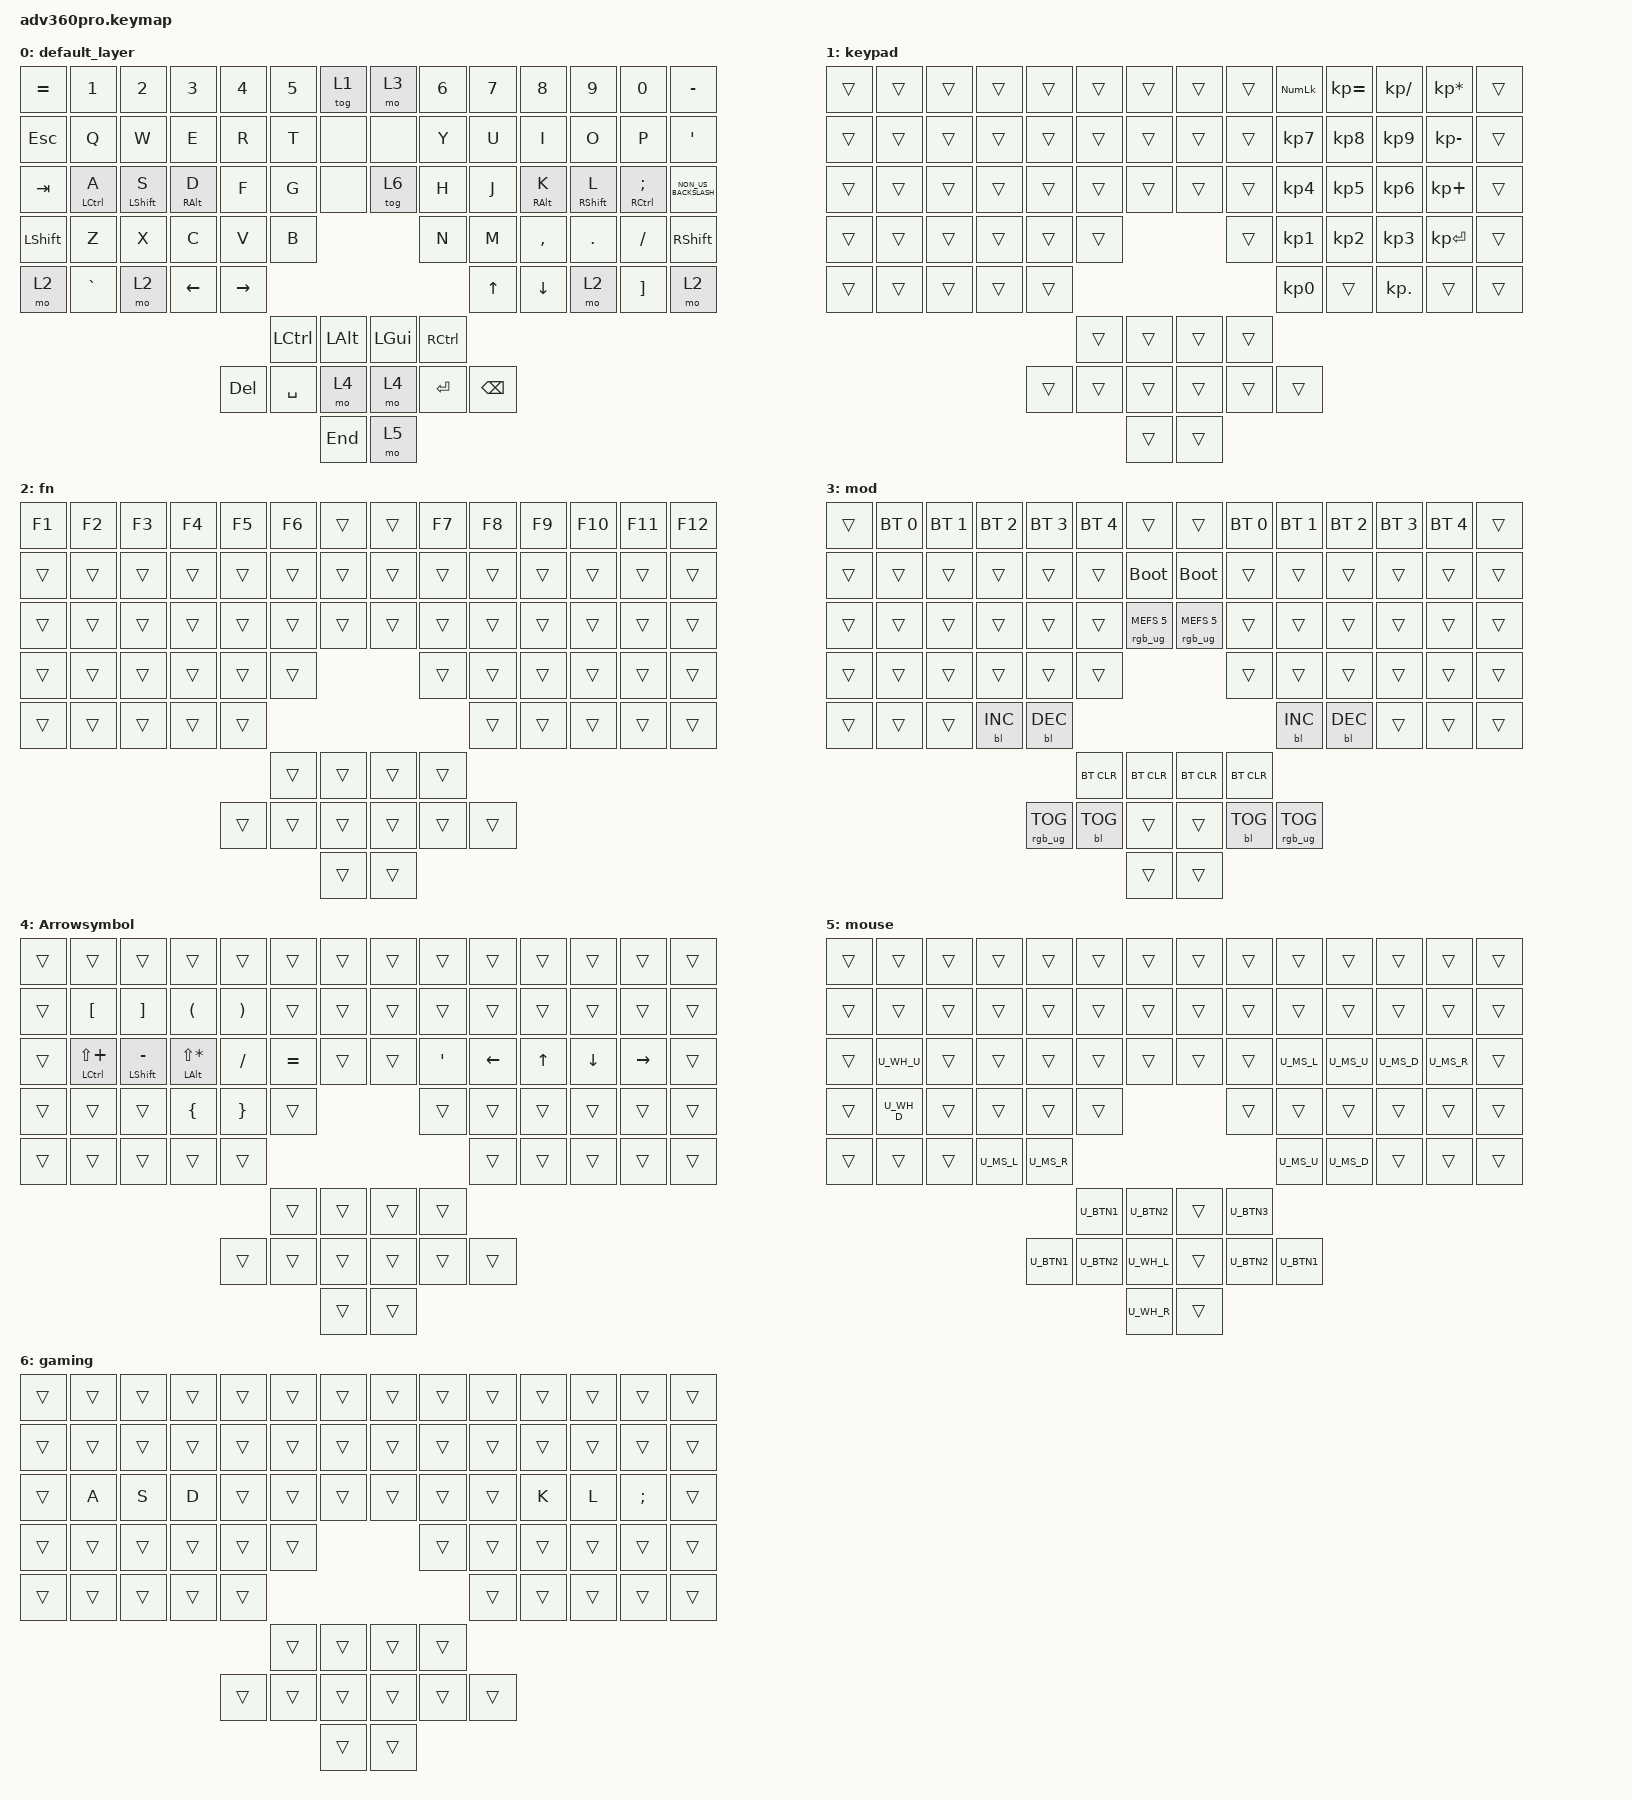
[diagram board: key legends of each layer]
#include <behaviors.dtsi>
#include <dt-bindings/zmk/backlight.h>
#include <dt-bindings/zmk/bt.h>
#include <dt-bindings/zmk/keys.h>
#include <dt-bindings/zmk/rgb.h>
#include "mouse.dtsi"
#define ___ &trans
/ {
    behaviors {
        hm_l: hm_l {
            compatible = "zmk,behavior-hold-tap";
            label = "HM_L";
            bindings =
                <&kp>,
                <&kp>;

            #binding-cells = <2>;
            flavor = "balanced";          
            tapping-term-ms = <280>;
            quick-tap-ms = <175>;                // repeat on tap-into-hold
            global-quick-tap-ms = <150>;         // requires PR #1387
            bindings = <&kp>, <&kp>;
            hold-trigger-key-positions = <7 8 9 10 11 12 13 21 22 23 24 25 26 27 35 36 37 38 39 40 41 48 49 50 51 52 53 59 60 61 62 63>;
            hold-trigger-on-release;             // delay positional check until key-release
        };
        hm_r: hm_r {
            compatible = "zmk,behavior-hold-tap";
            label = "HM_R";
            bindings =
                <&kp>,
                <&kp>;

            #binding-cells = <2>;
            flavor = "balanced";          
            tapping-term-ms = <280>;
            quick-tap-ms = <175>;                // repeat on tap-into-hold
            global-quick-tap-ms = <150>;         // requires PR #1387
            bindings = <&kp>, <&kp>;
            hold-trigger-key-positions = <0 1 2 3 4 5 6 14 15 16 17 18 19 20 28 29 30 31 32 33 34 42 43 44 45 46 47 54 55 56 57 58>;
            hold-trigger-on-release;             // delay positional check until key-release
        };
        
        
    };
    chosen {
        zmk,matrix_transform = &urobs_transform;
    };
    keymap {
        compatible = "zmk,keymap";

        default_layer {
            bindings = <
    &kp EQUAL   &kp N1          &kp N2          &kp N3          &kp N4      &kp N5      &tog 1      &mo 3       &kp N6      &kp N7      &kp N8          &kp N9          &kp N0                  &kp MINUS
    &kp ESC     &kp Q           &kp W           &kp E           &kp R       &kp T       &none       &none       &kp Y       &kp U       &kp I           &kp O           &kp P                   &kp SQT
    &kp TAB     &hm_l LCTRL A   &hm_l LSHIFT S  &hm_l RALT D    &kp F       &kp G       &none       &tog 6       &kp H       &kp J       &hm_r RALT K    &hm_r RSHIFT L  &hm_r RCTRL SEMICOLON   &kp NON_US_BACKSLASH
    &kp LSHFT   &kp Z           &kp X           &kp C           &kp V       &kp B                               &kp N       &kp M       &kp COMMA       &kp DOT         &kp FSLH                &kp RSHFT
    &mo 2      &kp GRAVE        &mo 2           &kp LEFT        &kp RIGHT                                                   &kp UP      &kp DOWN        &mo 2           &kp RBKT                &mo 2
                                                                            &kp LCTRL   &kp LALT    &kp LGUI    &kp RCTRL
                                                                &kp DEL     &kp SPACE   &mo 4       &mo 4       &kp ENTER   &kp BSPC
                                                                                        &kp END     &mo 5  
            >;
        };

        keypad {
            bindings = <
                ___       ___       ___       ___       ___       ___       ___            ___       ___       &kp KP_NUM &kp KP_EQUAL &kp KP_DIVIDE &kp KP_MULTIPLY ___
                ___       ___       ___       ___       ___       ___       ___            ___       ___       &kp KP_N7  &kp KP_N8    &kp KP_N9     &kp KP_MINUS    ___
                ___       ___       ___       ___       ___       ___       ___            ___       ___       &kp KP_N4  &kp KP_N5    &kp KP_N6     &kp KP_PLUS     ___
                ___       ___       ___       ___       ___       ___                                ___       &kp KP_N1  &kp KP_N2    &kp KP_N3     &kp KP_ENTER    ___
                ___       ___       ___       ___       ___                                                    &kp KP_N0  ___          &kp KP_DOT    ___             ___
                                                                  ___       ___            ___       ___
                                                        ___       ___       ___            ___       ___       ___
                                                                            ___            ___
            >;
        };

        fn {
            bindings = <
                &kp F1    &kp F2    &kp F3    &kp F4    &kp F5    &kp F6    ___            ___       &kp F7    &kp F8    &kp F9    &kp F10   &kp F11   &kp F12
                ___       ___       ___       ___       ___       ___       ___            ___       ___       ___       ___       ___       ___       ___
                ___       ___       ___       ___       ___       ___       ___            ___       ___       ___       ___       ___       ___       ___
                ___       ___       ___       ___       ___       ___                                ___       ___       ___       ___       ___       ___
                ___       ___       ___       ___       ___                                                    ___       ___       ___       ___       ___
                                                                  ___       ___            ___       ___
                                                        ___       ___       ___            ___       ___       ___
                                                                            ___            ___
            >;
        };

        mod {
            bindings = <
                ___       &bt BT_SEL 0 &bt BT_SEL 1 &bt BT_SEL 2 &bt BT_SEL 3    &bt BT_SEL 4 ___                           ___                     &bt BT_SEL 0 &bt BT_SEL 1     &bt BT_SEL 2 &bt BT_SEL 3 &bt BT_SEL 4 ___
                ___       ___          ___          ___          ___             ___          &bootloader                   &bootloader             ___          ___              ___          ___          ___          ___
                ___       ___          ___          ___          ___             ___          &rgb_ug RGB_MEFS_CMD 5        &rgb_ug RGB_MEFS_CMD 5  ___          ___              ___          ___          ___          ___
                ___       ___          ___          ___          ___             ___                                                                ___          ___              ___          ___          ___          ___
                ___       ___          ___          &bl BL_INC   &bl BL_DEC                                                                                      &bl BL_INC       &bl BL_DEC   ___          ___          ___
                                                                                 &bt BT_CLR   &bt BT_CLR                    &bt BT_CLR  &bt BT_CLR
                                                                 &rgb_ug RGB_TOG &bl BL_TOG   ___                           ___                     &bl BL_TOG   &rgb_ug RGB_TOG
                                                                                              ___                           ___
            >;
        };

        Arrowsymbol {
            bindings = <
                ___       ___                   ___                 ___                     ___                     ___       ___            ___       ___       ___       ___       ___       ___       ___
                ___       &kp LEFT_BRACKET      &kp RIGHT_BRACKET   &kp LEFT_PARENTHESIS    &kp RIGHT_PARENTHESIS   ___       ___            ___       ___       ___       ___       ___       ___       ___
                ___       &hm_l LCTRL LS(PLUS)  &hm_l LSHIFT MINUS  &hm_l LALT LS(ASTERISK) &kp SLASH               &kp EQUAL ___            ___       &kp SQT   &kp LEFT  &kp UP    &kp DOWN  &kp RIGHT ___
                ___       ___                   ___                 &kp LEFT_BRACE          &kp RIGHT_BRACE         ___                                ___       ___       ___       ___       ___       ___
                ___       ___                   ___                 ___                     ___                                                                  ___       ___       ___       ___       ___
                                                                                                                    ___       ___            ___       ___
                                                                                                          ___       ___       ___            ___       ___       ___
                                                                                                                              ___            ___
            >;
        };

        mouse {
            bindings = <
                ___       ___       ___       ___       ___       ___       ___            ___       ___       ___       ___       ___       ___       ___
                ___       ___       ___       ___       ___       ___       ___            ___       ___       ___       ___       ___       ___       ___
                ___       U_WH_U    ___       ___       ___       ___       ___            ___       ___       U_MS_L    U_MS_U    U_MS_D    U_MS_R    ___
                ___       U_WH_D    ___       ___       ___       ___                                ___       ___       ___       ___       ___       ___
                ___       ___       ___       U_MS_L    U_MS_R                                                 U_MS_U    U_MS_D    ___       ___       ___
                                                                  U_BTN1    U_BTN2         ___       U_BTN3
                                                        U_BTN1    U_BTN2    U_WH_L         ___       U_BTN2    U_BTN1
                                                                            U_WH_R         ___
            >;
        };
        gaming {
            bindings = <
    ___    ___      ___      ___      ___          ___          ___                 ___         ___    ___    ___      ___      ___              ___
    ___    ___      ___      ___      ___          ___          ___                 ___         ___    ___    ___      ___      ___              ___
    ___    &kp A    &kp S    &kp D    ___          ___          ___                 ___         ___    ___    &kp K    &kp L    &kp SEMICOLON    ___
    ___    ___      ___      ___      ___          ___                                          ___    ___    ___      ___      ___              ___
    ___    ___      ___      ___      ___                                                              ___    ___      ___      ___              ___
                                                   ___          ___                 ___         ___
                                      ___          ___          ___                 ___         ___    ___
                                                                ___                 ___ 
            >;
        };
    };
};
